# NVIC register map
Vendor: Texas Instruments
Peripheral module from a debugger description file (folder CC23x0R5).
Registers are 32-bit, access per field, reset 0x0 unless marked. A register's access mark holds for its fields unless they carry their own. Offsets are as the file gives them; lines under a group give offsets from that group; [hi:lo] are bit positions; {n}, {i} and the like mark numbered series; 'fields as' and 'values as' point back to an identical list; <NAME> marks a mode.

## NVIC
0x100 ISER rw — Interrupt Set-Enable Register Use the Interrupt Set-Enable Register to enable interrupts and determine which interrupts are currently enabled.
  [31:0] SETENA — Writing 0 to a SETENA bit has no effect, writing 1 to a bit enables the corresponding interrupt. Reading the bit returns its current enable state. Reset clears the SETENA fields.
0x180 ICER rw — Interrupt Clear-Enable Register Use the Interrupt Clear-Enable Registers to disable interrupts and determine which interrupts are currently enabled.
  [31:0] CLRENA — Writing 0 to a CLRENA bit has no effect, writing 1 to a bit disables the corresponding interrupt. Reading the bit returns its current enable state. Reset clears the CLRENA field.
0x200 ISPR rw — Interrupt Set-Pending Register Use the Interrupt Set-Pending Register to force interrupts into the pending state and determine which interrupts are currently pending
  [31:0] SETPEND — Interrupt set-pending bits for a: Write: 1 = pend interrupt 0 = no effect; Read: 1 = interrupt is pending 0 = interrupt is not pending.
0x280 ICPR rw — Interrupt Clear-Pending Register Use the Interrupt Clear-Pending Register to clear pending interrupts and determine which interrupts are currently pending.
  [31:0] CLRPEND — Interrupt clear-pending bits: Write: 1 = clear interrupt pending bit, 0 = no effect; Read: 1 = interrupt is pending 0 = interrupt is not pending.
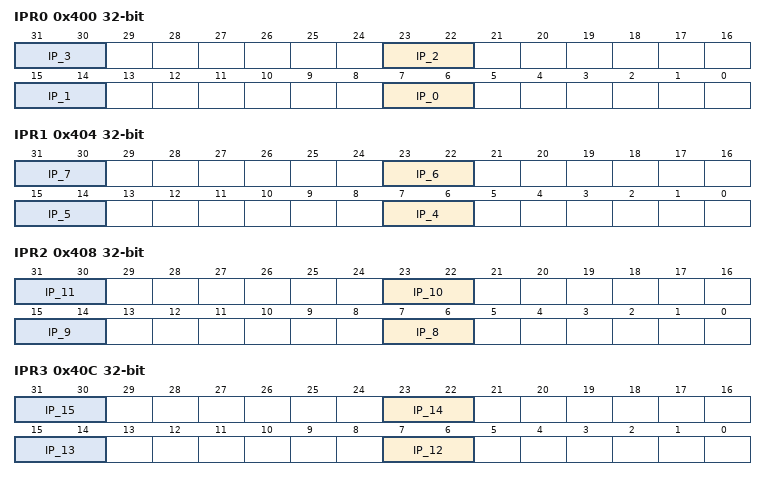
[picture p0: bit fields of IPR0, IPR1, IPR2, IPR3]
0x400 IPR0 — Interrupt Priority Register 0 Use the Interrupt Priority Registers to assign a priority from 0 to 3 to each of the available interrupts. 0 is the highest priority, and 3 is the lowest.
  [8n+7:8n+6] IP_{n} rw (n=0..3) — Priority of interrupt {n}
0x404 IPR1 — Interrupt Priority Register 1 Use the Interrupt Priority Registers to assign a priority from 0 to 3 to each of the available interrupts. 0 is the highest priority, and 3 is the lowest.
  [8n-25:8n-26] IP_{n} rw (n=4..7) — Priority of interrupt {n}
0x408 IPR2 — Interrupt Priority Register 2 Use the Interrupt Priority Registers to assign a priority from 0 to 3 to each of the available interrupts. 0 is the highest priority, and 3 is the lowest.
  [8n-57:8n-58] IP_{n} rw (n=8..11) — Priority of interrupt {n}
0x40C IPR3 — Interrupt Priority Register 3 Use the Interrupt Priority Registers to assign a priority from 0 to 3 to each of the available interrupts. 0 is the highest priority, and 3 is the lowest.
  [8n-89:8n-90] IP_{n} rw (n=12..15) — Priority of interrupt {n}
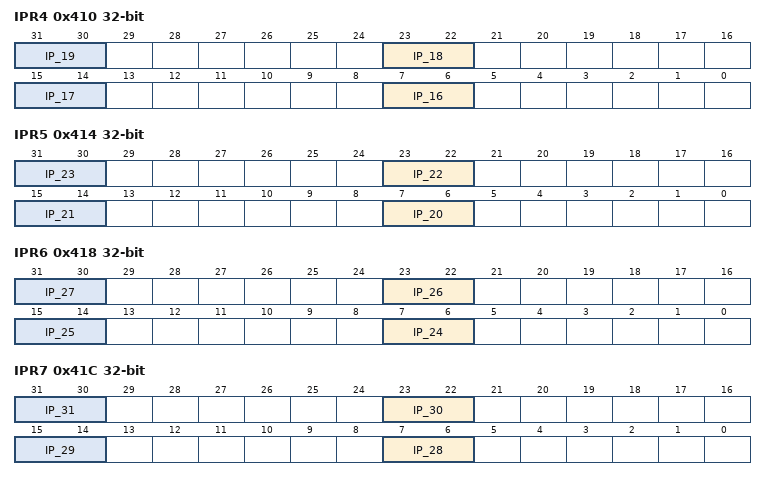
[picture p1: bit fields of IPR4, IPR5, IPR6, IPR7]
0x410 IPR4 — Interrupt Priority Register 4 Use the Interrupt Priority Registers to assign a priority from 0 to 3 to each of the available interrupts. 0 is the highest priority, and 3 is the lowest.
  [8n-121:8n-122] IP_{n} rw (n=16..19) — Priority of interrupt {n}
0x414 IPR5 — Interrupt Priority Register 5 Use the Interrupt Priority Registers to assign a priority from 0 to 3 to each of the available interrupts. 0 is the highest priority, and 3 is the lowest.
  [8n-153:8n-154] IP_{n} rw (n=20..23) — Priority of interrupt {n}
0x418 IPR6 — Interrupt Priority Register 6 Use the Interrupt Priority Registers to assign a priority from 0 to 3 to each of the available interrupts. 0 is the highest priority, and 3 is the lowest.
  [8n-185:8n-186] IP_{n} rw (n=24..27) — Priority of interrupt {n}
0x41C IPR7 — Interrupt Priority Register 7 Use the Interrupt Priority Registers to assign a priority from 0 to 3 to each of the available interrupts. 0 is the highest priority, and 3 is the lowest.
  [8n-217:8n-218] IP_{n} rw (n=28..31) — Priority of interrupt {n}
